VERSION ""

NS_ :

BS_:

BU_: ECU PDM

BO_ 1792 ChannelStatusRequest: 8 ECU
 SG_ ChannelNumber : 7|8@0+ (1,0) [1|14] "" Vector__XXX
 SG_ MathRuleSelector : 15|8@0+ (1,0) [0|8] "" Vector__XXX

BO_ 1793 ChannelStatusResponse: 8 PDM
 SG_ FrameIndex M : 7|8@0+ (1,0) [0|11] "" Vector__XXX
 SG_ ChannelType m0 : 15|8@0+ (1,0) [0|7] "" Vector__XXX
 SG_ ChannelCurrent m0 : 23|8@0+ (0.1,0) [0|25.5] "Amps" Vector__XXX
 SG_ Enabled m0 : 31|8@0+ (1,0) [0|1] "" Vector__XXX
 SG_ ChannelName m0 : 39|16@0+ (1,0) [0|32767] "PackedLetters" Vector__XXX
 SG_ CurrentThresholdLow m0 : 55|8@0+ (0.1,0) [0|17] "Amps" Vector__XXX
 SG_ CurrentThresholdHigh m0 : 63|8@0+ (0.1,0) [0|17] "Amps" Vector__XXX
 SG_ RetryCount m1 : 15|8@0+ (1,0) [0|255] "" Vector__XXX
 SG_ InrushDelay m1 : 23|32@0+ (1,0) [0|2000] "Milliseconds" Vector__XXX
 SG_ ActiveHigh m1 : 55|8@0+ (1,0) [0|1] "" Vector__XXX
 SG_ DelayedOn m1 : 63|8@0+ (1,0) [0|1] "" Vector__XXX
 SG_ DelayedOnTime m2 : 15|32@0+ (1,0) [0|3600000] "Milliseconds" Vector__XXX
 SG_ InrushCurrentThreshold m2 : 47|8@0+ (1,0) [0|50] "Amps" Vector__XXX
 SG_ DelayedOff m2 : 55|8@0+ (1,0) [0|1] "" Vector__XXX
 SG_ DelayedOffTrigger m2 : 63|8@0+ (1,0) [0|1] "" Vector__XXX
 SG_ DelayedOffTime m3 : 15|32@0+ (1,0) [0|3600000] "Milliseconds" Vector__XXX
 SG_ MathValueRaw m4 : 15|32@0+ (1,0) [0|4294967295] "IEEE754BE" Vector__XXX
 SG_ MathError m4 : 47|8@0+ (1,0) [0|4] "" Vector__XXX
 SG_ MathOutputMode m4 : 55|8@0+ (1,0) [0|1] "" Vector__XXX
 SG_ MathBooleanState m4 : 63|8@0+ (1,0) [0|1] "" Vector__XXX
 SG_ MathRuleCount m5 : 15|8@0+ (1,0) [1|8] "" Vector__XXX
 SG_ MathRootRule m5 : 23|8@0+ (1,0) [0|7] "" Vector__XXX
 SG_ MathOutputModeConfig m5 : 31|8@0+ (1,0) [0|1] "" Vector__XXX
 SG_ RequestedRule m5 : 39|8@0+ (1,0) [0|255] "" Vector__XXX
 SG_ RuleIndex m6 : 15|8@0+ (1,0) [0|7] "" Vector__XXX
 SG_ MathOperator m6 : 23|8@0+ (1,0) [0|16] "" Vector__XXX
 SG_ MathHysteresisEnabled m6 : 31|8@0+ (1,0) [0|1] "" Vector__XXX
 SG_ OperandAType m6 : 39|8@0+ (1,0) [0|6] "" Vector__XXX
 SG_ OperandAIndex m6 : 47|8@0+ (1,0) [0|99] "" Vector__XXX
 SG_ OperandBType m6 : 55|8@0+ (1,0) [0|6] "" Vector__XXX
 SG_ OperandBIndex m6 : 63|8@0+ (1,0) [0|99] "" Vector__XXX
 SG_ RuleIndex m7 : 15|8@0+ (1,0) [0|7] "" Vector__XXX
 SG_ OperandAConstantRaw m7 : 23|32@0+ (1,0) [0|4294967295] "IEEE754BE" Vector__XXX
 SG_ RuleIndex m8 : 15|8@0+ (1,0) [0|7] "" Vector__XXX
 SG_ OperandBConstantRaw m8 : 23|32@0+ (1,0) [0|4294967295] "IEEE754BE" Vector__XXX
 SG_ RuleIndex m9 : 15|8@0+ (1,0) [0|7] "" Vector__XXX
 SG_ RuleOnThresholdRaw m9 : 23|32@0+ (1,0) [0|4294967295] "IEEE754BE" Vector__XXX
 SG_ RuleIndex m10 : 15|8@0+ (1,0) [0|7] "" Vector__XXX
 SG_ RuleOffThresholdRaw m10 : 23|32@0+ (1,0) [0|4294967295] "IEEE754BE" Vector__XXX
 SG_ RuleIndex m11 : 15|8@0+ (1,0) [0|7] "" Vector__XXX
 SG_ RuleValueRaw m11 : 23|32@0+ (1,0) [0|4294967295] "IEEE754BE" Vector__XXX
 SG_ RuleError m11 : 55|8@0+ (1,0) [0|4] "" Vector__XXX
 SG_ RuleEvaluated m11 : 63|8@0+ (1,0) [0|1] "" Vector__XXX

BO_ 1808 DigitalInputStatusRequest: 8 ECU
 SG_ Reserved : 7|8@0+ (1,0) [0|0] "" Vector__XXX

BO_ 1809 DigitalInputStatusResponse: 8 PDM
 SG_ DigitalInputMask : 7|8@0+ (1,0) [0|255] "" Vector__XXX

BO_ 1810 AnalogueInputStatusRequest: 8 ECU
 SG_ InputNumber : 7|8@0+ (1,0) [1|8] "" Vector__XXX

BO_ 1811 AnalogueInputStatusResponse: 8 PDM
 SG_ FrameIndex M : 7|8@0+ (1,0) [0|1] "" Vector__XXX
 SG_ InputType m0 : 15|8@0+ (1,0) [0|4] "" Vector__XXX
 SG_ Units m0 : 23|8@0+ (1,0) [0|9] "" Vector__XXX
 SG_ Flags m0 : 31|8@0+ (1,0) [0|7] "" Vector__XXX
 SG_ InputVoltage m0 : 39|16@0+ (0.001,0) [0|65.535] "Volts" Vector__XXX
 SG_ ConvertedValue m1 : 15|32@0- (0.001,0) [-2147483.648|2147483.647] "EngineeringUnits" Vector__XXX

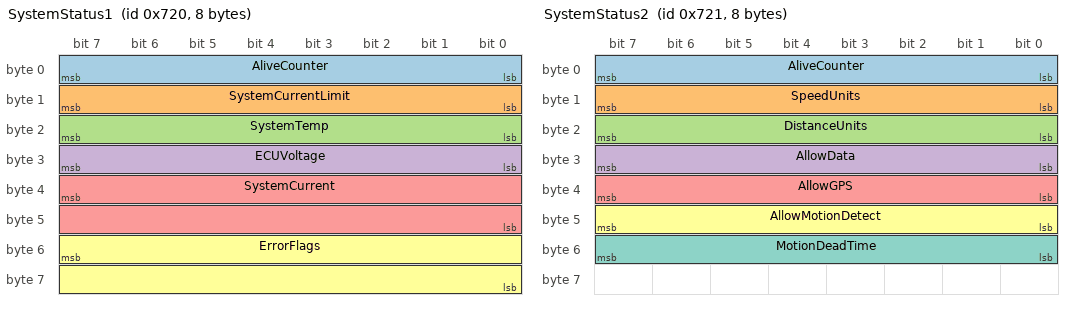
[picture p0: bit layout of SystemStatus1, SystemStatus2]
BO_ 1824 SystemStatus1: 8 PDM
 SG_ AliveCounter : 7|8@0+ (1,0) [0|255] "" Vector__XXX
 SG_ SystemCurrentLimit : 15|8@0+ (1,0) [0|150] "Amps" Vector__XXX
 SG_ SystemTemp : 23|8@0+ (1,0) [0|255] "Celsius" Vector__XXX
 SG_ ECUVoltage : 31|8@0+ (0.1,0) [0|25.5] "Volts" Vector__XXX
 SG_ SystemCurrent : 39|16@0+ (0.1,0) [0|6553.5] "Amps" Vector__XXX
 SG_ ErrorFlags : 55|16@0+ (1,0) [0|65535] "" Vector__XXX

CM_ SG_ 1824 ErrorFlags "Bit mask: 0x0001 Overcurrent, 0x0002 Overtemperature, 0x0004 Undervoltage, 0x0008 CRC check failed, 0x0010 SD card error, 0x0020 PC communications checksum error, 0x0040 GPS error, 0x0080 temperature warning, 0x0100 telemetry offline.";

BO_ 1825 SystemStatus2: 8 PDM
 SG_ AliveCounter : 7|8@0+ (1,0) [0|255] "" Vector__XXX
 SG_ SpeedUnits : 15|8@0+ (1,0) [0|1] "" Vector__XXX
 SG_ DistanceUnits : 23|8@0+ (1,0) [0|1] "" Vector__XXX
 SG_ AllowData : 31|8@0+ (1,0) [0|1] "" Vector__XXX
 SG_ AllowGPS : 39|8@0+ (1,0) [0|1] "" Vector__XXX
 SG_ AllowMotionDetect : 47|8@0+ (1,0) [0|1] "" Vector__XXX
 SG_ MotionDeadTime : 55|8@0+ (1,0) [0|254] "Minutes" Vector__XXX

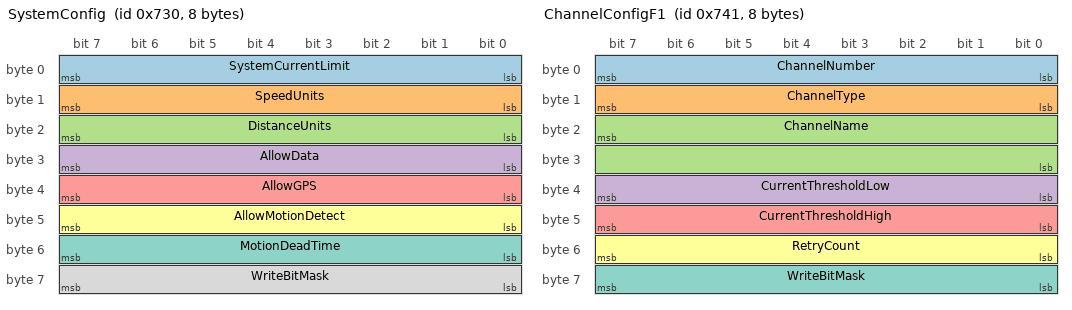
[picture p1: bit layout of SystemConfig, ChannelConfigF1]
BO_ 1840 SystemConfig: 8 ECU
 SG_ SystemCurrentLimit : 7|8@0+ (1,0) [0|150] "Amps" Vector__XXX
 SG_ SpeedUnits : 15|8@0+ (1,0) [0|1] "" Vector__XXX
 SG_ DistanceUnits : 23|8@0+ (1,0) [0|1] "" Vector__XXX
 SG_ AllowData : 31|8@0+ (1,0) [0|1] "" Vector__XXX
 SG_ AllowGPS : 39|8@0+ (1,0) [0|1] "" Vector__XXX
 SG_ AllowMotionDetect : 47|8@0+ (1,0) [0|1] "" Vector__XXX
 SG_ MotionDeadTime : 55|8@0+ (1,0) [0|254] "Minutes" Vector__XXX
 SG_ WriteBitMask : 63|8@0+ (1,0) [0|127] "" Vector__XXX

BO_ 1856 ChannelConfigF0: 8 ECU
 SG_ ChannelNumber : 7|8@0+ (1,0) [1|14] "" Vector__XXX
 SG_ ControlValue : 15|8@0+ (1,0) [0|255] "" Vector__XXX

BO_ 1857 ChannelConfigF1: 8 ECU
 SG_ ChannelNumber : 7|8@0+ (1,0) [1|14] "" Vector__XXX
 SG_ ChannelType : 15|8@0+ (1,0) [0|6] "" Vector__XXX
 SG_ ChannelName : 23|16@0+ (1,0) [0|32767] "PackedLetters" Vector__XXX
 SG_ CurrentThresholdLow : 39|8@0+ (0.1,0) [0|17] "Amps" Vector__XXX
 SG_ CurrentThresholdHigh : 47|8@0+ (0.1,0) [0|17] "Amps" Vector__XXX
 SG_ RetryCount : 55|8@0+ (1,0) [0|255] "" Vector__XXX
 SG_ WriteBitMask : 63|8@0+ (1,0) [0|127] "" Vector__XXX

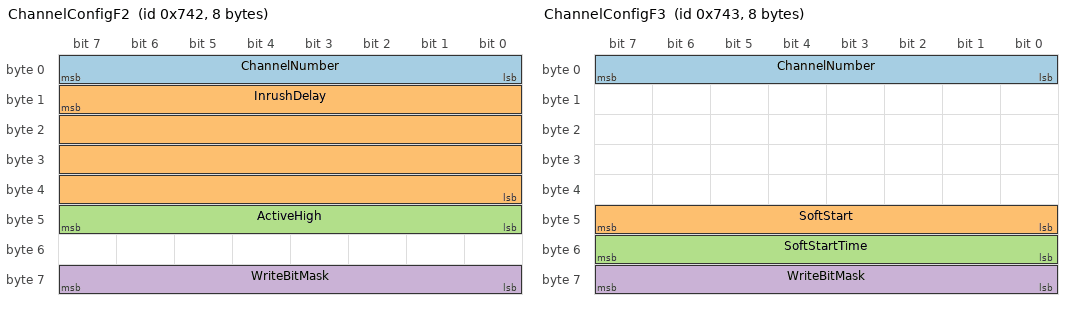
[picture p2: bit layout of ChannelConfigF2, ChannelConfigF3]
BO_ 1858 ChannelConfigF2: 8 ECU
 SG_ ChannelNumber : 7|8@0+ (1,0) [1|14] "" Vector__XXX
 SG_ InrushDelay : 15|32@0+ (1,0) [0|2000] "Milliseconds" Vector__XXX
 SG_ ActiveHigh : 47|8@0+ (1,0) [0|1] "" Vector__XXX
 SG_ WriteBitMask : 63|8@0+ (1,0) [0|7] "" Vector__XXX

BO_ 1859 ChannelConfigF3: 8 ECU
 SG_ ChannelNumber : 7|8@0+ (1,0) [1|14] "" Vector__XXX
 SG_ SoftStart : 47|8@0+ (1,0) [0|1] "" Vector__XXX
 SG_ SoftStartTime : 55|8@0+ (1,0) [0|5] "Seconds" Vector__XXX
 SG_ WriteBitMask : 63|8@0+ (1,0) [0|15] "" Vector__XXX

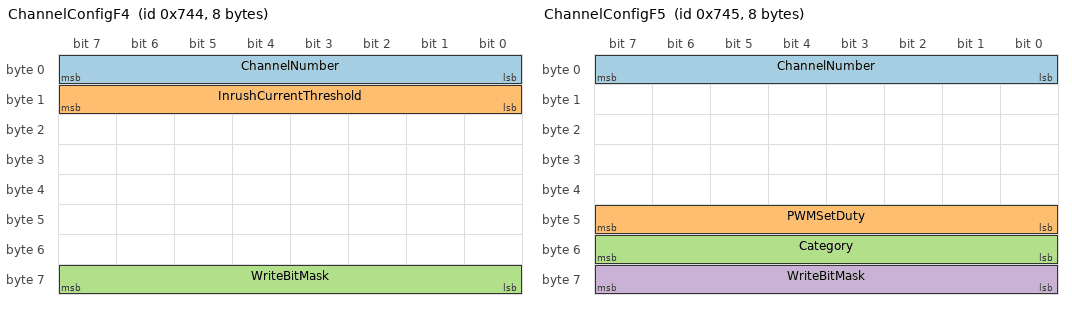
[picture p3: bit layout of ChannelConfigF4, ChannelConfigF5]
BO_ 1860 ChannelConfigF4: 8 ECU
 SG_ ChannelNumber : 7|8@0+ (1,0) [1|14] "" Vector__XXX
 SG_ InrushCurrentThreshold : 15|8@0+ (1,0) [0|50] "Amps" Vector__XXX
 SG_ WriteBitMask : 63|8@0+ (1,0) [0|1] "" Vector__XXX

BO_ 1861 ChannelConfigF5: 8 ECU
 SG_ ChannelNumber : 7|8@0+ (1,0) [1|14] "" Vector__XXX
 SG_ PWMSetDuty : 47|8@0+ (1,0) [0|100] "Percent" Vector__XXX
 SG_ Category : 55|8@0+ (1,0) [0|255] "" Vector__XXX
 SG_ WriteBitMask : 63|8@0+ (1,0) [0|255] "" Vector__XXX

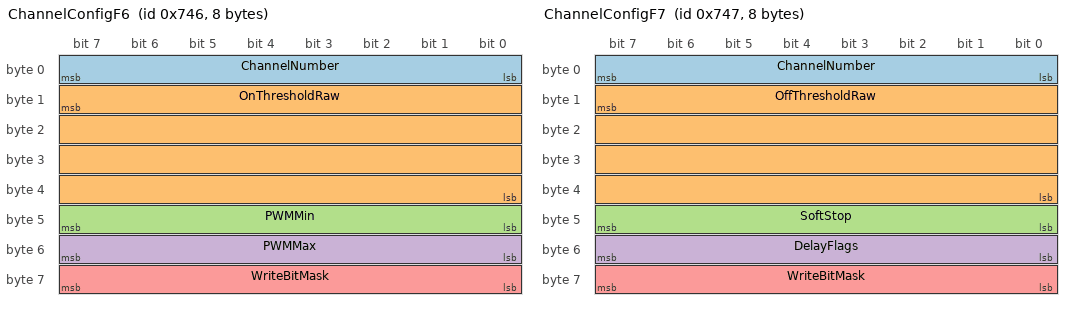
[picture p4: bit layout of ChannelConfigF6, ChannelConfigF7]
BO_ 1862 ChannelConfigF6: 8 ECU
 SG_ ChannelNumber : 7|8@0+ (1,0) [1|14] "" Vector__XXX
 SG_ OnThresholdRaw : 15|32@0+ (1,0) [0|4294967295] "IEEE754BE" Vector__XXX
 SG_ PWMMin : 47|8@0+ (1,0) [0|100] "Percent" Vector__XXX
 SG_ PWMMax : 55|8@0+ (1,0) [0|100] "Percent" Vector__XXX
 SG_ WriteBitMask : 63|8@0+ (1,0) [0|255] "" Vector__XXX

BO_ 1863 ChannelConfigF7: 8 ECU
 SG_ ChannelNumber : 7|8@0+ (1,0) [1|14] "" Vector__XXX
 SG_ OffThresholdRaw : 15|32@0+ (1,0) [0|4294967295] "IEEE754BE" Vector__XXX
 SG_ SoftStop : 47|8@0+ (1,0) [0|1] "" Vector__XXX
 SG_ DelayFlags : 55|8@0+ (1,0) [0|3] "" Vector__XXX
 SG_ WriteBitMask : 63|8@0+ (1,0) [0|255] "" Vector__XXX

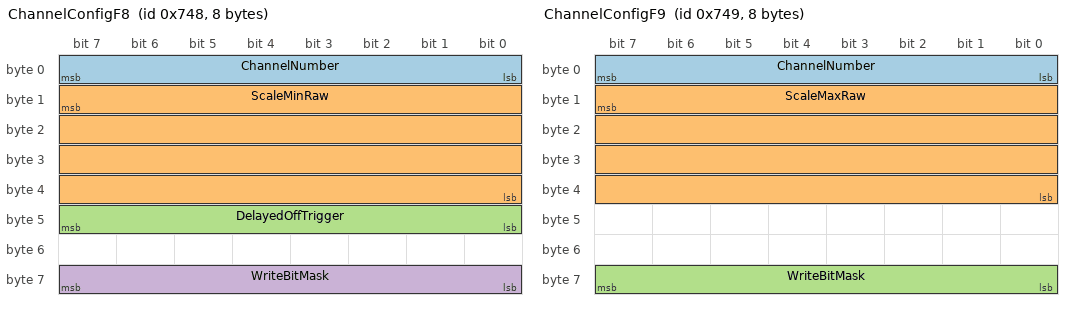
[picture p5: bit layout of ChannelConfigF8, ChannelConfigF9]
BO_ 1864 ChannelConfigF8: 8 ECU
 SG_ ChannelNumber : 7|8@0+ (1,0) [1|14] "" Vector__XXX
 SG_ ScaleMinRaw : 15|32@0+ (1,0) [0|4294967295] "IEEE754BE" Vector__XXX
 SG_ DelayedOffTrigger : 47|8@0+ (1,0) [0|1] "" Vector__XXX
 SG_ WriteBitMask : 63|8@0+ (1,0) [0|255] "" Vector__XXX

BO_ 1865 ChannelConfigF9: 8 ECU
 SG_ ChannelNumber : 7|8@0+ (1,0) [1|14] "" Vector__XXX
 SG_ ScaleMaxRaw : 15|32@0+ (1,0) [0|4294967295] "IEEE754BE" Vector__XXX
 SG_ WriteBitMask : 63|8@0+ (1,0) [0|1] "" Vector__XXX

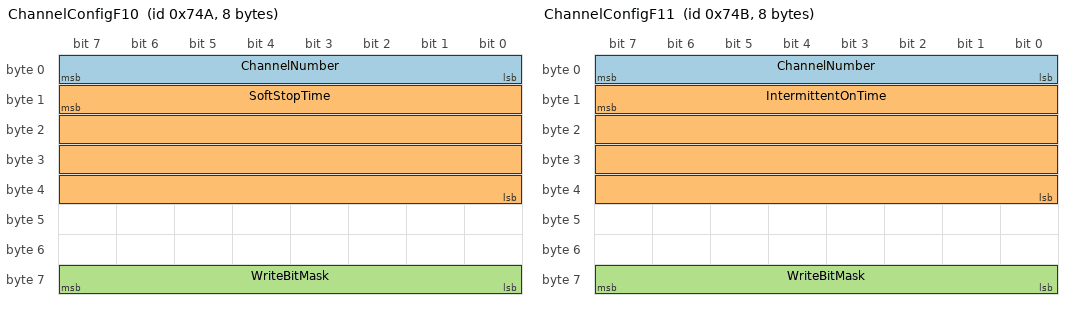
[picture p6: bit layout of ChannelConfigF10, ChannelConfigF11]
BO_ 1866 ChannelConfigF10: 8 ECU
 SG_ ChannelNumber : 7|8@0+ (1,0) [1|14] "" Vector__XXX
 SG_ SoftStopTime : 15|32@0+ (1,0) [0|5000] "Milliseconds" Vector__XXX
 SG_ WriteBitMask : 63|8@0+ (1,0) [0|1] "" Vector__XXX

BO_ 1867 ChannelConfigF11: 8 ECU
 SG_ ChannelNumber : 7|8@0+ (1,0) [1|14] "" Vector__XXX
 SG_ IntermittentOnTime : 15|32@0+ (1,0) [0|10000] "Milliseconds" Vector__XXX
 SG_ WriteBitMask : 63|8@0+ (1,0) [0|1] "" Vector__XXX

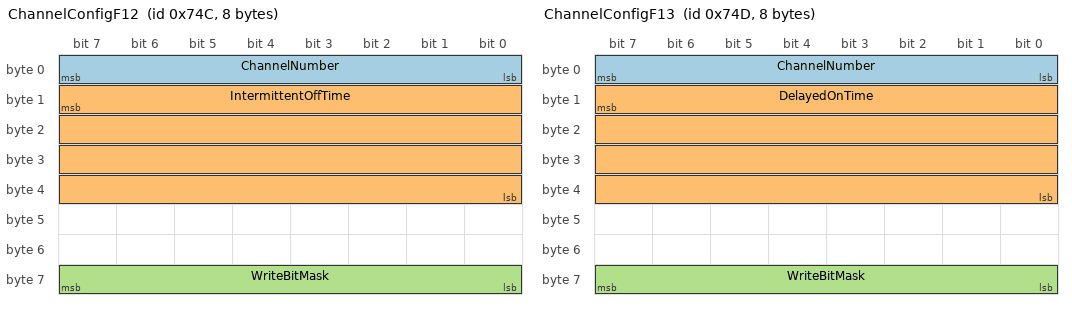
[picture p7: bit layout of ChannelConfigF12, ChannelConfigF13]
BO_ 1868 ChannelConfigF12: 8 ECU
 SG_ ChannelNumber : 7|8@0+ (1,0) [1|14] "" Vector__XXX
 SG_ IntermittentOffTime : 15|32@0+ (1,0) [0|10000] "Milliseconds" Vector__XXX
 SG_ WriteBitMask : 63|8@0+ (1,0) [0|1] "" Vector__XXX

BO_ 1869 ChannelConfigF13: 8 ECU
 SG_ ChannelNumber : 7|8@0+ (1,0) [1|14] "" Vector__XXX
 SG_ DelayedOnTime : 15|32@0+ (1,0) [0|3600000] "Milliseconds" Vector__XXX
 SG_ WriteBitMask : 63|8@0+ (1,0) [0|1] "" Vector__XXX

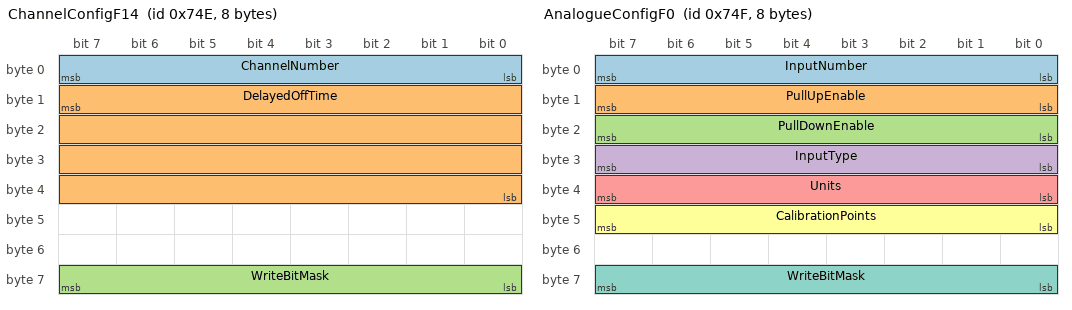
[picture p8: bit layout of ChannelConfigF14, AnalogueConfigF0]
BO_ 1870 ChannelConfigF14: 8 ECU
 SG_ ChannelNumber : 7|8@0+ (1,0) [1,0] [1|14] "" Vector__XXX
 SG_ DelayedOffTime : 15|32@0+ (1,0) [0|3600000] "Milliseconds" Vector__XXX
 SG_ WriteBitMask : 63|8@0+ (1,0) [0|1] "" Vector__XXX

BO_ 1871 AnalogueConfigF0: 8 ECU
 SG_ InputNumber : 7|8@0+ (1,0) [1|8] "" Vector__XXX
 SG_ PullUpEnable : 15|8@0+ (1,0) [0|1] "" Vector__XXX
 SG_ PullDownEnable : 23|8@0+ (1,0) [0|1] "" Vector__XXX
 SG_ InputType : 31|8@0+ (1,0) [0|4] "" Vector__XXX
 SG_ Units : 39|8@0+ (1,0) [0|9] "" Vector__XXX
 SG_ CalibrationPoints : 47|8@0+ (1,0) [2|3] "" Vector__XXX
 SG_ WriteBitMask : 63|8@0+ (1,0) [0|31] "" Vector__XXX

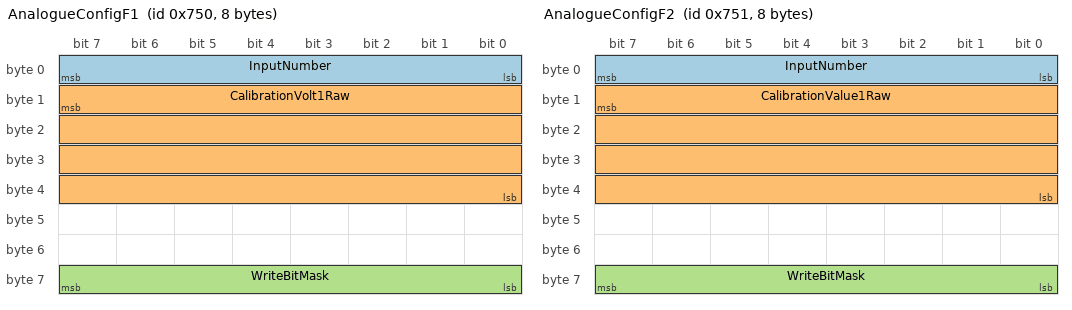
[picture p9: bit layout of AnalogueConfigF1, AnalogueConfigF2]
BO_ 1872 AnalogueConfigF1: 8 ECU
 SG_ InputNumber : 7|8@0+ (1,0) [1|8] "" Vector__XXX
 SG_ CalibrationVolt1Raw : 15|32@0+ (1,0) [0|4294967295] "IEEE754BE" Vector__XXX
 SG_ WriteBitMask : 63|8@0+ (1,0) [0|1] "" Vector__XXX

BO_ 1873 AnalogueConfigF2: 8 ECU
 SG_ InputNumber : 7|8@0+ (1,0) [1|8] "" Vector__XXX
 SG_ CalibrationValue1Raw : 15|32@0+ (1,0) [0|4294967295] "IEEE754BE" Vector__XXX
 SG_ WriteBitMask : 63|8@0+ (1,0) [0|1] "" Vector__XXX

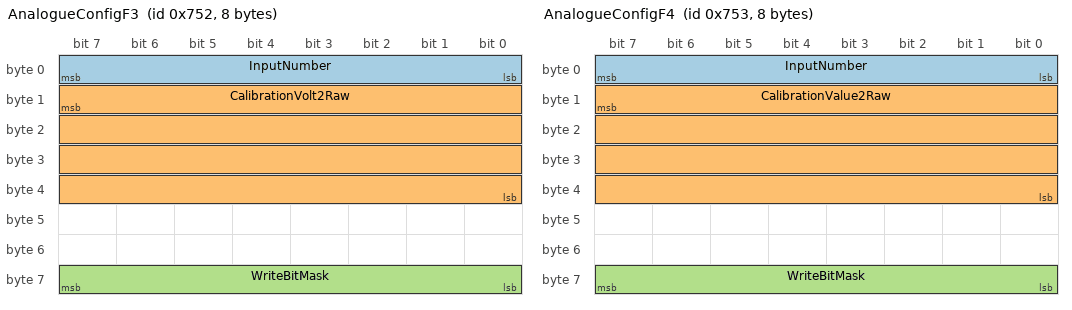
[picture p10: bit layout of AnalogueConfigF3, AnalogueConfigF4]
BO_ 1874 AnalogueConfigF3: 8 ECU
 SG_ InputNumber : 7|8@0+ (1,0) [1|8] "" Vector__XXX
 SG_ CalibrationVolt2Raw : 15|32@0+ (1,0) [0|4294967295] "IEEE754BE" Vector__XXX
 SG_ WriteBitMask : 63|8@0+ (1,0) [0|1] "" Vector__XXX

BO_ 1875 AnalogueConfigF4: 8 ECU
 SG_ InputNumber : 7|8@0+ (1,0) [1|8] "" Vector__XXX
 SG_ CalibrationValue2Raw : 15|32@0+ (1,0) [0|4294967295] "IEEE754BE" Vector__XXX
 SG_ WriteBitMask : 63|8@0+ (1,0) [0|1] "" Vector__XXX

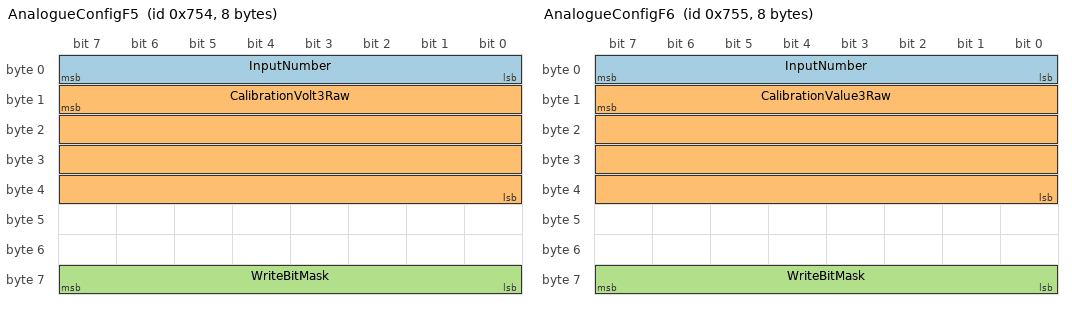
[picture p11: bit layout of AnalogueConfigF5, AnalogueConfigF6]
BO_ 1876 AnalogueConfigF5: 8 ECU
 SG_ InputNumber : 7|8@0+ (1,0) [1|8] "" Vector__XXX
 SG_ CalibrationVolt3Raw : 15|32@0+ (1,0) [0|4294967295] "IEEE754BE" Vector__XXX
 SG_ WriteBitMask : 63|8@0+ (1,0) [0|1] "" Vector__XXX

BO_ 1877 AnalogueConfigF6: 8 ECU
 SG_ InputNumber : 7|8@0+ (1,0) [1|8] "" Vector__XXX
 SG_ CalibrationValue3Raw : 15|32@0+ (1,0) [0|4294967295] "IEEE754BE" Vector__XXX
 SG_ WriteBitMask : 63|8@0+ (1,0) [0|1] "" Vector__XXX

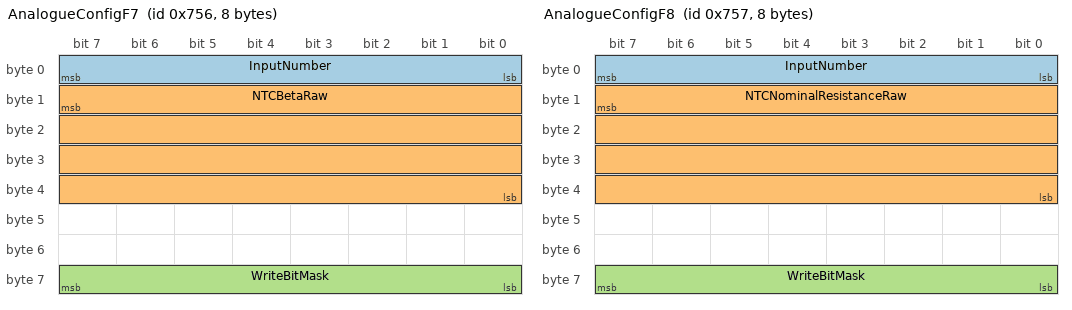
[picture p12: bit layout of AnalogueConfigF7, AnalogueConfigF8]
BO_ 1878 AnalogueConfigF7: 8 ECU
 SG_ InputNumber : 7|8@0+ (1,0) [1|8] "" Vector__XXX
 SG_ NTCBetaRaw : 15|32@0+ (1,0) [0|4294967295] "IEEE754BE" Vector__XXX
 SG_ WriteBitMask : 63|8@0+ (1,0) [0|1] "" Vector__XXX

BO_ 1879 AnalogueConfigF8: 8 ECU
 SG_ InputNumber : 7|8@0+ (1,0) [1|8] "" Vector__XXX
 SG_ NTCNominalResistanceRaw : 15|32@0+ (1,0) [0|4294967295] "IEEE754BE" Vector__XXX
 SG_ WriteBitMask : 63|8@0+ (1,0) [0|1] "" Vector__XXX

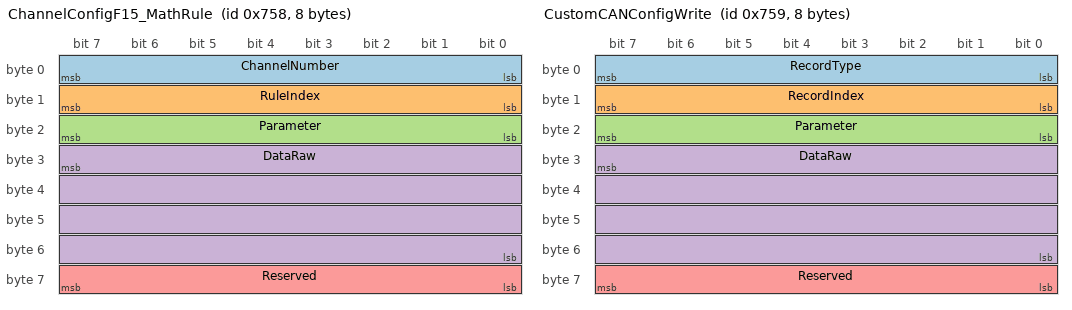
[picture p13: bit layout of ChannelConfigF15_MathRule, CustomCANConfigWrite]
BO_ 1880 ChannelConfigF15_MathRule: 8 ECU
 SG_ ChannelNumber : 7|8@0+ (1,0) [1|14] "" Vector__XXX
 SG_ RuleIndex : 15|8@0+ (1,0) [0|255] "" Vector__XXX
 SG_ Parameter : 23|8@0+ (1,0) [0|12] "" Vector__XXX
 SG_ DataRaw : 31|32@0+ (1,0) [0|4294967295] "uint32 or IEEE754BE" Vector__XXX
 SG_ Reserved : 63|8@0+ (1,0) [0|0] "" Vector__XXX

BO_ 1881 CustomCANConfigWrite: 8 ECU
 SG_ RecordType : 7|8@0+ (1,0) [0|1] "" Vector__XXX
 SG_ RecordIndex : 15|8@0+ (1,0) [0|99] "" Vector__XXX
 SG_ Parameter : 23|8@0+ (1,0) [0|5] "" Vector__XXX
 SG_ DataRaw : 31|32@0+ (1,0) [0|4294967295] "uint32 or IEEE754BE" Vector__XXX
 SG_ Reserved : 63|8@0+ (1,0) [0|0] "" Vector__XXX

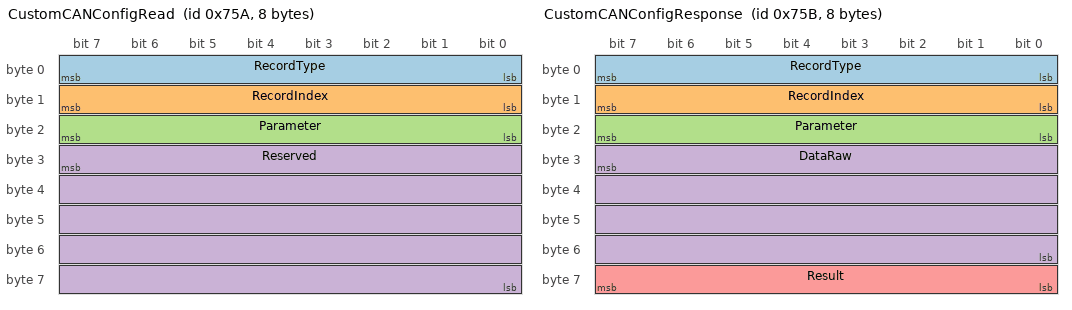
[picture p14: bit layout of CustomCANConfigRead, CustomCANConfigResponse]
BO_ 1882 CustomCANConfigRead: 8 ECU
 SG_ RecordType : 7|8@0+ (1,0) [0|1] "" Vector__XXX
 SG_ RecordIndex : 15|8@0+ (1,0) [0|99] "" Vector__XXX
 SG_ Parameter : 23|8@0+ (1,0) [0|7] "" Vector__XXX
 SG_ Reserved : 31|40@0+ (1,0) [0|0] "" Vector__XXX

BO_ 1883 CustomCANConfigResponse: 8 PDM
 SG_ RecordType : 7|8@0+ (1,0) [0|1] "" Vector__XXX
 SG_ RecordIndex : 15|8@0+ (1,0) [0|99] "" Vector__XXX
 SG_ Parameter : 23|8@0+ (1,0) [0|7] "" Vector__XXX
 SG_ DataRaw : 31|32@0+ (1,0) [0|4294967295] "uint32 or IEEE754BE" Vector__XXX
 SG_ Result : 63|8@0+ (1,0) [0|1] "" Vector__XXX

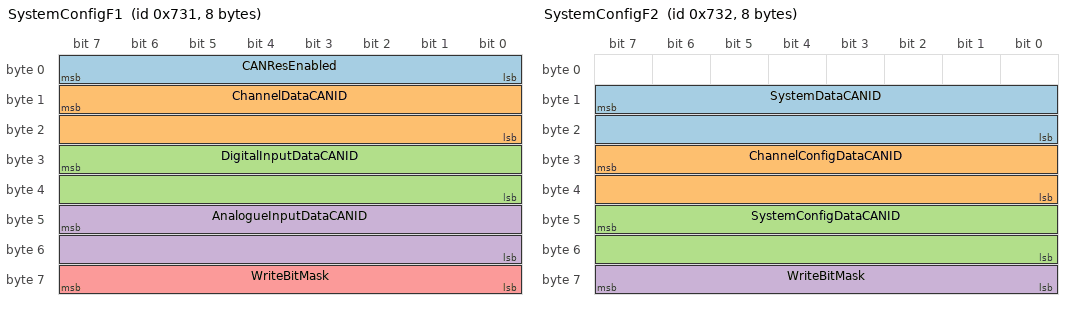
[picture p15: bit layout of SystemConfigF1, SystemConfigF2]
BO_ 1841 SystemConfigF1: 8 ECU
 SG_ CANResEnabled : 7|8@0+ (1,0) [0|1] "" Vector__XXX
 SG_ ChannelDataCANID : 15|16@0+ (1,0) [0|2047] "" Vector__XXX
 SG_ DigitalInputDataCANID : 31|16@0+ (1,0) [0|2047] "" Vector__XXX
 SG_ AnalogueInputDataCANID : 47|16@0+ (1,0) [0|2047] "" Vector__XXX
 SG_ WriteBitMask : 63|8@0+ (1,0) [0|15] "" Vector__XXX

BO_ 1842 SystemConfigF2: 8 ECU
 SG_ SystemDataCANID : 15|16@0+ (1,0) [0|2047] "" Vector__XXX
 SG_ ChannelConfigDataCANID : 31|16@0+ (1,0) [1|2020] "" Vector__XXX
 SG_ SystemConfigDataCANID : 47|16@0+ (1,0) [0|2047] "" Vector__XXX
 SG_ WriteBitMask : 63|8@0+ (1,0) [0|7] "" Vector__XXX

BO_ 1843 SystemConfigF3: 8 ECU
 SG_ IMUwakeWindow : 31|32@0+ (1,0) [0|4294967295] "Milliseconds" Vector__XXX
 SG_ WriteBitMask : 63|8@0+ (1,0) [0|1] "" Vector__XXX

BO_ 1844 SystemConfigF4: 8 ECU
 SG_ CANBusBitrate : 31|32@0+ (1,0) [125000|1000000] "BitsPerSecond" Vector__XXX
 SG_ WriteBitMask : 63|8@0+ (1,0) [0|1] "" Vector__XXX

BO_ 1845 SystemConfigF5: 8 ECU
 SG_ TimeZoneRuleBytes0_7 : 7|64@0+ (1,0) [0|18446744073709551615] "RawBytes" Vector__XXX

BO_ 1846 SystemConfigF6: 8 ECU
 SG_ TimeZoneRuleBytes8_14 : 7|56@0+ (1,0) [0|72057594037927935] "RawBytes" Vector__XXX

CM_ BO_ 1792 "Request a single channel status block. Set ChannelNumber to 1..14.";
CM_ BO_ 1793 "Multiplexed response on ChannelDataCANID + 1. FrameIndex selects the payload layout; request byte 1 selects a MATH rule for frames 6-11.";
CM_ SG_ 1793 FrameIndex "0-3 = existing channel status, 4 = MATH root value/state, 5 = MATH graph metadata, 6 = selected rule, 7-10 = selected rule constants/thresholds, 11 = selected rule runtime.";
CM_ SG_ 1793 ChannelName "Three uppercase letters packed into 16 bits as ((c0-'A') << 10) | ((c1-'A') << 5) | (c2-'A').";
CM_ BO_ 1808 "Digital input snapshot request. Payload is ignored by the controller.";
CM_ BO_ 1809 "Digital input snapshot response.";
CM_ SG_ 1809 DigitalInputMask "Bit 0 = DI1 through bit 7 = DI8. Set means the sampled input is logically high.";
CM_ BO_ 1810 "Request a single analogue input snapshot. Set InputNumber to 1..8.";
CM_ BO_ 1811 "Multiplexed 2-frame response on AnalogueInputDataCANID + 1. FrameIndex selects metadata or live value.";
CM_ SG_ 1811 FrameIndex "0 = input metadata and source voltage, 1 = converted live engineering value.";
CM_ SG_ 1811 Flags "Bit 0 = PullUpEnable, bit 1 = PullDownEnable, bit 2 = current logical digital state after pull-direction interpretation.";
CM_ SG_ 1811 ConvertedValue "Signed engineering value scaled by 1000. Interpret using the Units signal from frame 0.";
CM_ SG_ 1824 AliveCounter "Post-incrementing status counter. SystemStatus1 carries the pre-increment value.";
CM_ SG_ 1824 ECUVoltage "Battery voltage encoded as VBatt * 10.";
CM_ SG_ 1824 ErrorFlags "Bitmask: 0x0001 Overcurrent, 0x0002 Overtemp, 0x0004 Undervoltage, 0x0008 CRC check failed, 0x0010 SD card error, 0x0020 PC comms checksum error, 0x0040 GPS error, 0x0080 Temperature warning.";
CM_ SG_ 1825 AliveCounter "Second status frame uses the incremented counter value from SystemStatus1.";
CM_ BO_ 1840 "System configuration write message.";
CM_ SG_ 1840 WriteBitMask "Bits 0..6 gate bytes 0..6 respectively. Bit 0 = SystemCurrentLimit, bit 6 = MotionDeadTime.";
CM_ BO_ 1856 "Basic channel control message. Byte 1 is the only control byte used by firmware.";
CM_ SG_ 1856 ControlValue "0 disables the channel. Any non-zero value enables it. For CAN_PWM channels, the same byte is also taken as the PWM duty when the value is 100 or below.";
CM_ BO_ 1857 "Extended channel configuration write. Firmware reads byte 0 = ChannelNumber, byte 1 = ChannelType, bytes 2-3 = ChannelName, byte 4 = CurrentThresholdLow, byte 5 = CurrentThresholdHigh, byte 6 = RetryCount, byte 7 = WriteBitMask. Motorola start bits 23, 39, 47, and 55 therefore map to bytes 2, 4, 5, and 6 respectively.";
CM_ SG_ 1857 ChannelName "Three uppercase letters packed into 16 bits as ((c0-'A') << 10) | ((c1-'A') << 5) | (c2-'A').";
CM_ SG_ 1857 WriteBitMask "Bits 0,1,3,4,5 are implemented for ChannelType, ChannelName, CurrentThresholdLow, CurrentThresholdHigh, and RetryCount. Bit 2 is unused. Firmware also checks bit 6, but byte 7 is the mask itself, so use ChannelConfigF4 to set InrushCurrentThreshold.";
CM_ SG_ 1858 WriteBitMask "Bits 1 and 2 gate InrushDelay and ActiveHigh respectively. Bits 0 and 3 are unused.";
CM_ SG_ 1859 WriteBitMask "Bits 2 and 3 gate SoftStart and SoftStartTime respectively. Bits 0 and 1 are unused.";
CM_ BO_ 1860 "Dedicated inrush current threshold write message. Firmware reads byte 0 = ChannelNumber, byte 1 = InrushCurrentThreshold, byte 7 = WriteBitMask, and ignores bytes 2-6.";
CM_ SG_ 1860 WriteBitMask "Bit 0 gates InrushCurrentThreshold. When clear, the controller ignores byte 1. Bytes 2-6 are unused padding and should be sent as zero.";
CM_ BO_ 1861 "ChannelConfigF5 writes stored PWMSetDuty and Category. Only WriteBitMask bits 4 and 5 are implemented; bytes 1-4 remain reserved.";
CM_ BO_ 1862 "ChannelConfigF6 writes OnThreshold plus PWMMin/PWMMax for analogue/scaled channel modes.";
CM_ BO_ 1863 "ChannelConfigF7 writes OffThreshold, SoftStop, and delayed-on/off enable flags packed into DelayFlags.";
CM_ SG_ 1863 DelayFlags "Bit 0 = DelayedOn, bit 1 = DelayedOff.";
CM_ BO_ 1864 "ChannelConfigF8 writes ScaleMin and DelayedOffTrigger.";
CM_ BO_ 1865 "ChannelConfigF9 writes ScaleMax using bytes 1-4 as a raw big-endian IEEE-754 float.";
CM_ BO_ 1866 "ChannelConfigF10 writes SoftStopTime in milliseconds using bytes 1-4.";
CM_ BO_ 1867 "ChannelConfigF11 writes IntermittentOnTime in milliseconds using bytes 1-4.";
CM_ BO_ 1868 "ChannelConfigF12 writes IntermittentOffTime in milliseconds using bytes 1-4.";
CM_ BO_ 1869 "ChannelConfigF13 writes DelayedOnTime in milliseconds using bytes 1-4.";
CM_ BO_ 1870 "ChannelConfigF14 writes DelayedOffTime in milliseconds using bytes 1-4.";
CM_ BO_ 1871 "AnalogueConfigF0 writes analogue input flags, type, units, and calibration-point count.";
CM_ BO_ 1872 "AnalogueConfigF1 writes CalibrationVolt1 using bytes 1-4 as a raw big-endian IEEE-754 float.";
CM_ BO_ 1873 "AnalogueConfigF2 writes CalibrationValue1 using bytes 1-4 as a raw big-endian IEEE-754 float.";
CM_ BO_ 1874 "AnalogueConfigF3 writes CalibrationVolt2 using bytes 1-4 as a raw big-endian IEEE-754 float.";
CM_ BO_ 1875 "AnalogueConfigF4 writes CalibrationValue2 using bytes 1-4 as a raw big-endian IEEE-754 float.";
CM_ BO_ 1876 "AnalogueConfigF5 writes CalibrationVolt3 using bytes 1-4 as a raw big-endian IEEE-754 float.";
CM_ BO_ 1877 "AnalogueConfigF6 writes CalibrationValue3 using bytes 1-4 as a raw big-endian IEEE-754 float.";
CM_ BO_ 1878 "AnalogueConfigF7 writes NTCBeta using bytes 1-4 as a raw big-endian IEEE-754 float.";
CM_ BO_ 1879 "AnalogueConfigF8 writes NTCNominalResistance using bytes 1-4 as a raw big-endian IEEE-754 float.";
CM_ BO_ 1880 "ChannelConfigF15 (ChannelConfigDataCANID + 24) writes one MATH channel or indexed rule parameter. Byte 1 is 0xFF for channel metadata or 0-7 for a rule; byte 2 is the parameter; bytes 3-6 are the uint32 or big-endian IEEE-754 payload.";
CM_ BO_ 1881 "ChannelConfigDataCANID + 25. Type 0=message: parameters 0=ID, 1=timeout ms (1-60000), 2=DLC (1-8), 3=flags (bit0 enabled, bit1 extended). Type 1=signal: 0=message index, 1=start bit, 2=bit length (1-64), 3=flags (bit0 enabled, bit1 Motorola, bit2 signed), 4=factor float, 5=offset float. All indices zero-based. Writes validated before applying; response on base+27.";
CM_ BO_ 1882 "ChannelConfigDataCANID + 26. Same selectors as CustomCANConfigWrite; additionally message parameter 4=status, signal 6=value float (fails if unavailable), 7=status. Response on base+27.";
CM_ BO_ 1883 "ChannelConfigDataCANID + 27. Echoes selectors and write value or returns read value. Result 0=accepted, 1=rejected/unavailable. Status values: 0=valid, 1=disabled, 2=not received, 3=timeout, 4=invalid frame, 5=decode error, 6=invalid config.";
VAL_ 1793 OperandAType 0 "Constant" 1 "Channel" 2 "AnalogueInput" 3 "SystemValue" 4 "Rule" 5 "DigitalInput" 6 "CustomCANSignal" ;
VAL_ 1793 OperandBType 0 "Constant" 1 "Channel" 2 "AnalogueInput" 3 "SystemValue" 4 "Rule" 5 "DigitalInput" 6 "CustomCANSignal" ;
VAL_ 1881 RecordType 0 "Message" 1 "Signal" ;
VAL_ 1882 RecordType 0 "Message" 1 "Signal" ;
VAL_ 1883 RecordType 0 "Message" 1 "Signal" ;
VAL_ 1883 Result 0 "Accepted" 1 "RejectedOrUnavailable" ;
CM_ BO_ 1841 "SystemConfigF1 writes CAN termination and request CAN IDs not covered by SystemConfig.";
CM_ BO_ 1842 "SystemConfigF2 writes the remaining status/config CAN IDs.";
CM_ BO_ 1843 "SystemConfigF3 writes IMUwakeWindow in milliseconds using bytes 0-3.";
CM_ BO_ 1844 "SystemConfigF4 writes CANBusBitrate in bits per second using bytes 0-3. Firmware only accepts supported presets.";
CM_ BO_ 1845 "SystemConfigF5 carries TimeZoneRule bytes 0-7. Firmware buffers this frame until SystemConfigF6 arrives.";
CM_ BO_ 1846 "SystemConfigF6 carries TimeZoneRule bytes 8-14 in bytes 0-6. Firmware applies the packed rule once both timezone frames have arrived.";
CM_ SG_ 1841 WriteBitMask "Bit 0 gates CANResEnabled, bit 1 ChannelDataCANID, bit 2 DigitalInputDataCANID, bit 3 AnalogueInputDataCANID.";
CM_ SG_ 1842 WriteBitMask "Bit 0 gates SystemDataCANID, bit 1 ChannelConfigDataCANID, bit 2 SystemConfigDataCANID.";
CM_ SG_ 1843 WriteBitMask "Bit 0 gates IMUwakeWindow. Bytes 4-6 are unused padding and should be sent as zero.";
CM_ SG_ 1844 WriteBitMask "Bit 0 gates CANBusBitrate. Bytes 4-6 are unused padding and should be sent as zero.";
VAL_ 1793 FrameIndex 0 "Frame0" 1 "Frame1" 2 "Frame2" 3 "Frame3" ;
VAL_ 1793 ChannelType 0 "Digital" 1 "DigitalPWM" 2 "AnalogueThreshold" 3 "AnalogueScaled" 4 "CANDigital" 5 "CANPWM" 6 "DigitalIntermittent" ;
VAL_ 1793 Enabled 0 "OutputOff" 1 "OutputOn" ;
VAL_ 1793 ActiveHigh 0 "ActiveLow" 1 "ActiveHigh" ;
VAL_ 1793 DelayedOn 0 "Disabled" 1 "Enabled" ;
VAL_ 1793 DelayedOff 0 "Disabled" 1 "Enabled" ;
VAL_ 1793 DelayedOffTrigger 0 "AssignedInput" 1 "IgnitionOff" ;
VAL_ 1811 FrameIndex 0 "Frame0" 1 "Frame1" ;
VAL_ 1811 InputType 0 "RawVoltage" 1 "Active" 2 "Passive" 3 "NTC" 4 "Digital" ;
VAL_ 1811 Units 0 "Volts" 1 "Amps" 2 "Celsius" 3 "Fahrenheit" 4 "Percent" 5 "RPM" 6 "KPH" 7 "MPH" 8 "Bar" 9 "PSI" ;
VAL_ 1825 SpeedUnits 0 "Metric" 1 "Imperial" ;
VAL_ 1825 DistanceUnits 0 "Metric" 1 "Imperial" ;
VAL_ 1825 AllowData 0 "False" 1 "True" ;
VAL_ 1825 AllowGPS 0 "False" 1 "True" ;
VAL_ 1825 AllowMotionDetect 0 "False" 1 "True" ;
VAL_ 1840 SpeedUnits 0 "Metric" 1 "Imperial" ;
VAL_ 1840 DistanceUnits 0 "Metric" 1 "Imperial" ;
VAL_ 1840 AllowData 0 "False" 1 "True" ;
VAL_ 1840 AllowGPS 0 "False" 1 "True" ;
VAL_ 1840 AllowMotionDetect 0 "False" 1 "True" ;
VAL_ 1857 ChannelType 0 "Digital" 1 "DigitalPWM" 2 "AnalogueThreshold" 3 "AnalogueScaled" 4 "CANDigital" 5 "CANPWM" 6 "DigitalIntermittent" ;
VAL_ 1858 ActiveHigh 0 "ActiveLow" 1 "ActiveHigh" ;
VAL_ 1859 SoftStart 0 "Disabled" 1 "Enabled" ;
VAL_ 1863 SoftStop 0 "Disabled" 1 "Enabled" ;
VAL_ 1864 DelayedOffTrigger 0 "AssignedInput" 1 "IgnitionOff" ;
VAL_ 1871 PullUpEnable 0 "False" 1 "True" ;
VAL_ 1871 PullDownEnable 0 "False" 1 "True" ;
VAL_ 1871 InputType 0 "RawVoltage" 1 "Active" 2 "Passive" 3 "NTC" 4 "Digital" ;
VAL_ 1871 Units 0 "Volts" 1 "Amps" 2 "Celsius" 3 "Fahrenheit" 4 "Percent" 5 "RPM" 6 "KPH" 7 "MPH" 8 "Bar" 9 "PSI" ;
VAL_ 1841 CANResEnabled 0 "Disabled" 1 "Enabled" ;
